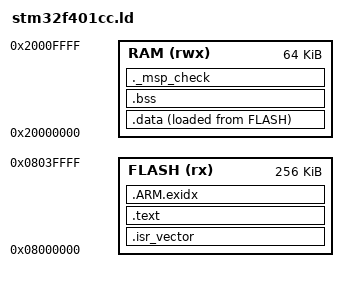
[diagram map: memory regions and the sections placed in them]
/* Linker script for STM32F401CCU6: 256 KB flash, 64 KB RAM */

ENTRY(Reset_Handler)

MEMORY
{
    FLASH (rx)  : ORIGIN = 0x08000000, LENGTH = 256K
    RAM   (rwx) : ORIGIN = 0x20000000, LENGTH = 64K
}

/* main stack (MSP): used before the scheduler starts and by interrupts after */
_estack = ORIGIN(RAM) + LENGTH(RAM);
_min_msp_size = 0x800;

SECTIONS
{
    .isr_vector :
    {
        . = ALIGN(4);
        KEEP(*(.isr_vector))
        . = ALIGN(4);
    } > FLASH

    .text :
    {
        . = ALIGN(4);
        *(.text*)
        *(.rodata*)
        KEEP(*(.init))
        KEEP(*(.fini))
        . = ALIGN(4);
        _etext = .;
    } > FLASH

    .ARM.exidx :
    {
        *(.ARM.exidx*)
    } > FLASH

    _sidata = LOADADDR(.data);

    .data :
    {
        . = ALIGN(4);
        _sdata = .;
        *(.data*)
        . = ALIGN(4);
        _edata = .;
    } > RAM AT > FLASH

    .bss (NOLOAD) :
    {
        . = ALIGN(4);
        _sbss = .;
        *(.bss*)
        *(COMMON)
        . = ALIGN(4);
        _ebss = .;
    } > RAM

    /* fail the link if there is no room left for the main stack */
    ._msp_check (NOLOAD) :
    {
        . = ALIGN(8);
        . = . + _min_msp_size;
    } > RAM
}
